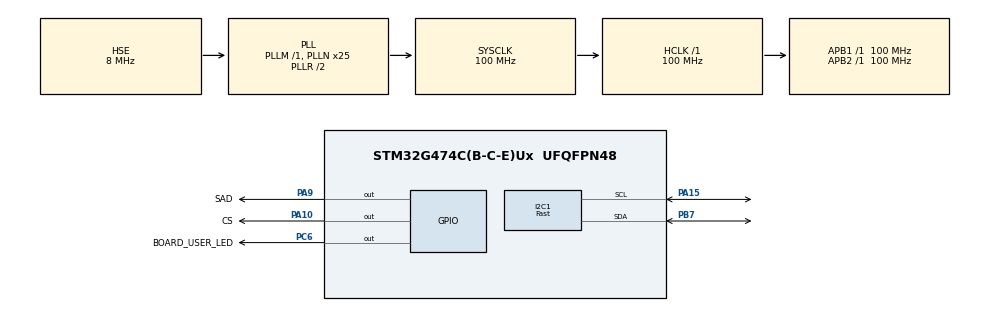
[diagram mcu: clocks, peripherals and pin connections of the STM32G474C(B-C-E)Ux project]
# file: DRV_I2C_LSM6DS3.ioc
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I2C1.I2C_Speed_Mode=I2C_Fast
I2C1.Speed=350
I2C1.Timing=0x009053BB
Mcu.Family=STM32G4
Mcu.Name=STM32G474C(B-C-E)Ux
Mcu.Package=UFQFPN48
NVIC.PriorityGroup=NVIC_PRIORITYGROUP_4
PA10.GPIO_Label=CS
PA10.Signal=GPIO_Output
PA13.Mode=Serial_Wire
PA13.Signal=SYS_JTMS-SWDIO
PA14.Mode=Serial_Wire
PA14.Signal=SYS_JTCK-SWCLK
PA15.Mode=I2C
PA15.Signal=I2C1_SCL
PA9.GPIO_Label=SAD
PA9.Signal=GPIO_Output
PB7.Mode=I2C
PB7.Signal=I2C1_SDA
PC6.GPIO_Label=BOARD_USER_LED
PC6.Signal=GPIO_Output
PF0-OSC_IN.Mode=HSE-External-Oscillator
PF0-OSC_IN.Signal=RCC_OSC_IN
PF1-OSC_OUT.Mode=HSE-External-Oscillator
PF1-OSC_OUT.Signal=RCC_OSC_OUT
ProjectManager.HeapSize=0x200
ProjectManager.StackSize=0x400
ProjectManager.TargetToolchain=STM32CubeIDE
RCC.ADC12Freq_Value=100000000
RCC.ADC345Freq_Value=100000000
RCC.AHBFreq_Value=100000000
RCC.APB1Freq_Value=100000000
RCC.APB1TimFreq_Value=100000000
RCC.APB2Freq_Value=100000000
RCC.APB2TimFreq_Value=100000000
RCC.CortexFreq_Value=100000000
RCC.EXTERNAL_CLOCK_VALUE=12288000
RCC.HCLKFreq_Value=100000000
RCC.HSE_VALUE=8000000
RCC.HSI48_VALUE=48000000
RCC.HSI_VALUE=16000000
RCC.LSE_VALUE=32768
RCC.PLLN=25
RCC.PLLSourceVirtual=RCC_PLLSOURCE_HSE
RCC.SYSCLKFreq_VALUE=100000000
RCC.SYSCLKSource=RCC_SYSCLKSOURCE_PLLCLK
RCC.USBFreq_Value=100000000
RCC.VCOOutputFreq_Value=200000000
VP_SYS_VS_DBSignals.Mode=DisableDeadBatterySignals
board=custom

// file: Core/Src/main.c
/* USER CODE BEGIN Header */
/**
  ******************************************************************************
  * @file           : main.c
  * @brief          : Main program body
  ******************************************************************************
  * @attention
  *
  * Copyright (c) 2025 STMicroelectronics.
  * All rights reserved.
  *
  * This software is licensed under terms that can be found in the LICENSE file
  * in the root directory of this software component.
  * If no LICENSE file comes with this software, it is provided AS-IS.
  *
  ******************************************************************************
  */
/* USER CODE END Header */
#include "main.h"
#include "i2c.h"
#include "gpio.h"

void SystemClock_Config(void);

int main(void)
{

  /* MCU Configuration--------------------------------------------------------*/

  /* Reset of all peripherals, Initializes the Flash interface and the Systick. */
  HAL_Init();

  /* Configure the system clock */
  SystemClock_Config();

  /* Initialize all configured peripherals */
  MX_GPIO_Init();
  MX_I2C1_Init();
  /* USER CODE BEGIN 2 */
  LSM6DS3_Init();
  HAL_Delay(1);

  /* USER CODE END 2 */

  /* Infinite loop */
  /* USER CODE BEGIN WHILE */
  while (1)
  {
    LSM6DS3_ACCEL_Read();
    LSM6DS3_Gyro_Read();
    HAL_Delay(200);

    /* USER CODE END WHILE */

  }
}

void SystemClock_Config(void)
{
  RCC_OscInitTypeDef RCC_OscInitStruct = {0};
  RCC_ClkInitTypeDef RCC_ClkInitStruct = {0};

  /** Configure the main internal regulator output voltage
  */
  HAL_PWREx_ControlVoltageScaling(PWR_REGULATOR_VOLTAGE_SCALE1);

  /** Initializes the RCC Oscillators according to the specified parameters
  * in the RCC_OscInitTypeDef structure.
  */
  RCC_OscInitStruct.OscillatorType = RCC_OSCILLATORTYPE_HSE;
  RCC_OscInitStruct.HSEState = RCC_HSE_ON;
  RCC_OscInitStruct.PLL.PLLState = RCC_PLL_ON;
  RCC_OscInitStruct.PLL.PLLSource = RCC_PLLSOURCE_HSE;
  RCC_OscInitStruct.PLL.PLLM = RCC_PLLM_DIV1;
  RCC_OscInitStruct.PLL.PLLN = 25;
  RCC_OscInitStruct.PLL.PLLP = RCC_PLLP_DIV2;
  RCC_OscInitStruct.PLL.PLLQ = RCC_PLLQ_DIV2;
  RCC_OscInitStruct.PLL.PLLR = RCC_PLLR_DIV2;
  if (HAL_RCC_OscConfig(&RCC_OscInitStruct) != HAL_OK)
  {
    Error_Handler();
  }

  /** Initializes the CPU, AHB and APB buses clocks
  */
  RCC_ClkInitStruct.ClockType = RCC_CLOCKTYPE_HCLK|RCC_CLOCKTYPE_SYSCLK
                              |RCC_CLOCKTYPE_PCLK1|RCC_CLOCKTYPE_PCLK2;
  RCC_ClkInitStruct.SYSCLKSource = RCC_SYSCLKSOURCE_PLLCLK;
  RCC_ClkInitStruct.AHBCLKDivider = RCC_SYSCLK_DIV1;
  RCC_ClkInitStruct.APB1CLKDivider = RCC_HCLK_DIV1;
  RCC_ClkInitStruct.APB2CLKDivider = RCC_HCLK_DIV1;

  if (HAL_RCC_ClockConfig(&RCC_ClkInitStruct, FLASH_LATENCY_3) != HAL_OK)
  {
    Error_Handler();
  }
}

/* USER CODE BEGIN 4 */
/*--------------------For debug--------------------*/
int _write(int file, uint8_t *ptr, int len)
{
  int DataIdx;
  for (DataIdx = 0; DataIdx < len; DataIdx++)
  {
    ITM_SendChar(*ptr++);
  }
  return len;
}
/*------------------End for debug------------------*/
/* USER CODE END 4 */

void Error_Handler(void)
{
  __disable_irq();
  while (1)
  {
  }
}
